AUTOSAR XML (schema 314)
package /ComponentType
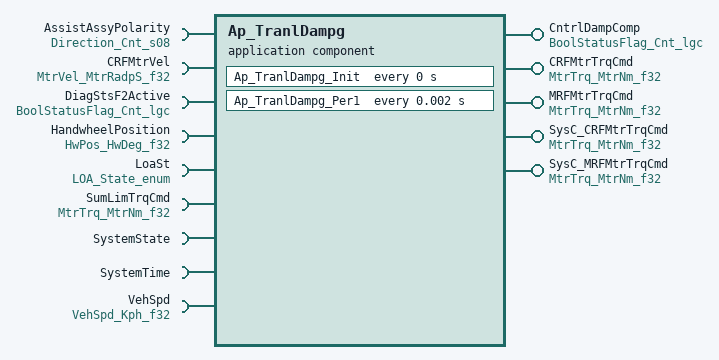
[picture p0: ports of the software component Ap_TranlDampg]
  application software component type Ap_TranlDampg
    5 x provide port:
      CntrlDampComp: unqueued-sender-com-spec{data-element=Cnt_lgc, can-invalidate=false, init-value=D_FALSE_CNT_LGC}, provided-interface=BoolStatusFlag_Cnt_lgc
      CRFMtrTrqCmd: unqueued-sender-com-spec{data-element=MtrNm_f32, can-invalidate=false, init-value=D_ZERO_ULS_F32}, provided-interface=MtrTrq_MtrNm_f32
      MRFMtrTrqCmd: unqueued-sender-com-spec{data-element=MtrNm_f32, can-invalidate=false, init-value=D_ZERO_ULS_F32}, provided-interface=MtrTrq_MtrNm_f32
      SysC_CRFMtrTrqCmd: unqueued-sender-com-spec{data-element=MtrNm_f32, can-invalidate=false, init-value=D_ZERO_ULS_F32}, provided-interface=MtrTrq_MtrNm_f32
      SysC_MRFMtrTrqCmd: unqueued-sender-com-spec{data-element=MtrNm_f32, can-invalidate=false, init-value=D_ZERO_ULS_F32}, provided-interface=MtrTrq_MtrNm_f32
    9 x require port:
      AssistAssyPolarity: unqueued-receiver-com-spec{data-element=Cnt_s08, init-value=D_ZERO_CNT_S8}, required-interface=Direction_Cnt_s08
      CRFMtrVel: unqueued-receiver-com-spec{data-element=MtrRadpS_f32, init-value=D_ZERO_ULS_F32}, required-interface=MtrVel_MtrRadpS_f32
      DiagStsF2Active: unqueued-receiver-com-spec{data-element=Cnt_lgc, init-value=D_FALSE_CNT_LGC}, required-interface=BoolStatusFlag_Cnt_lgc
      HandwheelPosition: unqueued-receiver-com-spec{data-element=HwDeg_f32, init-value=D_ZERO_ULS_F32}, required-interface=HwPos_HwDeg_f32
      LoaSt: unqueued-receiver-com-spec{data-element=State_enum, init-value=D_LOASTATEINIT_CNT_ENUM}, required-interface=LOA_State_enum
      SumLimTrqCmd: unqueued-receiver-com-spec{data-element=MtrNm_f32, init-value=D_ZERO_ULS_F32}, required-interface=MtrTrq_MtrNm_f32
      SystemState: required-interface=SystemState
      SystemTime: required-interface=SystemTime
        required-com-specs:
          DtrmnElapsedTime_mS_u16
          DtrmnElapsedTime_mS_u32
          DtrmnElapsedTime_uS_u16
          DtrmnElapsedTime_uS_u32
          GetSystemTime_mS_u32
          GetSystemTime_uS_u32
      VehSpd: unqueued-receiver-com-spec{data-element=Kph_f32, init-value=D_ZERO_ULS_F32}, required-interface=VehSpd_Kph_f32
  internal behavior Ap_TranlDampg_InternalBehavior: component=Ap_TranlDampg
    timing event Ap_TranlDampg_InitEvent: start-on-event=Ap_TranlDampg_Init, period=0
    timing event TMT_Ap_TranlDampg_Per1: start-on-event=Ap_TranlDampg_Per1, period=0.002
    port-api-options:
      enable-take-address=false, indirect-api=false, port=AssistAssyPolarity
      enable-take-address=false, indirect-api=false, port=CntrlDampComp
      enable-take-address=false, indirect-api=false, port=CRFMtrTrqCmd
      enable-take-address=false, indirect-api=false, port=CRFMtrVel
      enable-take-address=false, indirect-api=false, port=DiagStsF2Active
      enable-take-address=false, indirect-api=false, port=HandwheelPosition
      enable-take-address=false, indirect-api=false, port=LoaSt
      enable-take-address=false, indirect-api=false, port=MRFMtrTrqCmd
      enable-take-address=false, indirect-api=false, port=SumLimTrqCmd
      enable-take-address=false, indirect-api=false, port=SysC_CRFMtrTrqCmd
      enable-take-address=false, indirect-api=false, port=SysC_MRFMtrTrqCmd
      enable-take-address=false, indirect-api=false, port=SystemState
      enable-take-address=false, indirect-api=false, port=SystemTime
      enable-take-address=false, indirect-api=false, port=VehSpd
    runnable Ap_TranlDampg_Init
    runnable Ap_TranlDampg_Per1
      7 x data read access:
        READ_AssistAssyPolarity_Cnt_s08: data-element=AssistAssyPolarity.Cnt_s08
        READ_CRFMtrVel_MtrRadpS_f32: data-element=CRFMtrVel.MtrRadpS_f32
        READ_DiagStsF2Active_Cnt_lgc: data-element=DiagStsF2Active.Cnt_lgc
        READ_HandwheelPosition_HwDeg_f32: data-element=HandwheelPosition.HwDeg_f32
        READ_LoaSt_State_enum: data-element=LoaSt.State_enum
        READ_SumLimTrqCmd_MtrNm_f32: data-element=SumLimTrqCmd.MtrNm_f32
        READ_VehSpd_Kph_f32: data-element=VehSpd.Kph_f32
      5 x data write access:
        WRITE_CntrlDampComp_Cnt_lgc: data-element=CntrlDampComp.Cnt_lgc
        WRITE_CRFMtrTrqCmd_MtrNm_f32: data-element=CRFMtrTrqCmd.MtrNm_f32
        WRITE_MRFMtrTrqCmd_MtrNm_f32: data-element=MRFMtrTrqCmd.MtrNm_f32
        WRITE_SysC_CRFMtrTrqCmd_MtrNm_f32: data-element=SysC_CRFMtrTrqCmd.MtrNm_f32
        WRITE_SysC_MRFMtrTrqCmd_MtrNm_f32: data-element=SysC_MRFMtrTrqCmd.MtrNm_f32
      sync call SC_SystemTime_DtrmnElapsedTime_mS_u16: operation=SystemTime.DtrmnElapsedTime_mS_u16, timeout=0
      sync call SC_SystemTime_GetSystemTime_mS_u32: operation=SystemTime.GetSystemTime_mS_u32, timeout=0
  swc implementation Ap_TranlDampg_Implementation: behavior=Ap_TranlDampg_InternalBehavior
    code-descriptors:
      code Code: type=SRC
